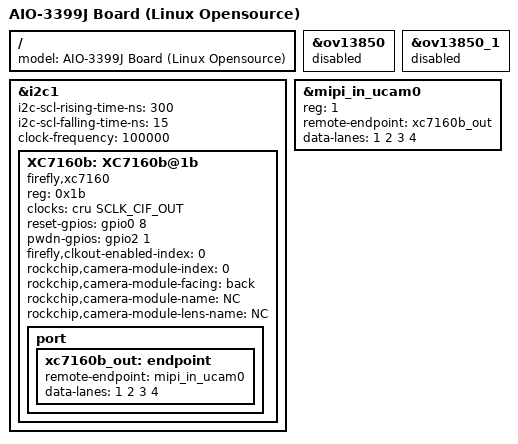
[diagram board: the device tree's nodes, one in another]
/*
 * Copyright (c) 2016 Fuzhou Rockchip Electronics Co., Ltd
 *
 * This file is dual-licensed: you can use it either under the terms
 * of the GPL or the X11 license, at your option. Note that this dual
 * licensing only applies to this file, and not this project as a
 * whole.
 *
 *  a) This file is free software; you can redistribute it and/or
 *     modify it under the terms of the GNU General Public License as
 *     published by the Free Software Foundation; either version 2 of the
 *     License, or (at your option) any later version.
 *
 *     This file is distributed in the hope that it will be useful,
 *     but WITHOUT ANY WARRANTY; without even the implied warranty of
 *     MERCHANTABILITY or FITNESS FOR A PARTICULAR PURPOSE.  See the
 *     GNU General Public License for more details.
 *
 * Or, alternatively,
 *     restriction, including without limitation the rights to use,
 *     copy, modify, merge, publish, distribute, sublicense, and/or
 *     sell copies of the Software, and to permit persons to whom the
 *     Software is furnished to do so, subject to the following
 *     conditions:
 *
 *     The above copyright notice and this permission notice shall be
 *     included in all copies or substantial portions of the Software.
 *
 *     THE SOFTWARE IS PROVIDED "AS IS", WITHOUT WARRANTY OF ANY KIND,
 *     EXPRESS OR IMPLIED, INCLUDING BUT NOT LIMITED TO THE WARRANTIES
 *     OF MERCHANTABILITY, FITNESS FOR A PARTICULAR PURPOSE AND
 *     NONINFRINGEMENT. IN NO EVENT SHALL THE AUTHORS OR COPYRIGHT
 *     HOLDERS BE LIABLE FOR ANY CLAIM, DAMAGES OR OTHER LIABILITY,
 *     WHETHER IN AN ACTION OF CONTRACT, TORT OR OTHERWISE, ARISING
 *     FROM, OUT OF OR IN CONNECTION WITH THE SOFTWARE OR THE USE OR
 *     OTHER DEALINGS IN THE SOFTWARE.
 */

/dts-v1/;

#include "rk3399-firefly-aio.dtsi"

/ {
	model = "AIO-3399J Board (Linux Opensource)";
};


&ov13850 {
	status = "disabled";
};

&ov13850_1 {
	status = "disabled";
};


&i2c1 {
	status = "okay";
	i2c-scl-rising-time-ns = <300>;
	i2c-scl-falling-time-ns = <15>;
	clock-frequency = <100000>;

	XC7160b: XC7160b@1b{
        status = "okay";
        compatible = "firefly,xc7160";
        reg = <0x1b>;
        clocks = <&cru SCLK_CIF_OUT>;
        clock-names = "xvclk";

        reset-gpios = <&gpio0 8 GPIO_ACTIVE_HIGH>;	/*GPIO0_B0 MIP_RST*/
		pwdn-gpios = <&gpio2 1 GPIO_ACTIVE_HIGH>;	/*GPIO2_A1  DVP_PDN1_H*/
		pinctrl-names = "rockchip,camera_default", "rockchip,camera_sleep";

        firefly,clkout-enabled-index = <0>;
        rockchip,camera-module-index = <0>;
        rockchip,camera-module-facing = "back";
        rockchip,camera-module-name = "NC";
        rockchip,camera-module-lens-name = "NC";
        port {
			xc7160b_out: endpoint {
				remote-endpoint = <&mipi_in_ucam0>;
                data-lanes = <1 2 3 4>;
            };
        };
    };
};


&mipi_in_ucam0 {
    reg = <1>;
    remote-endpoint = <&xc7160b_out>;
    data-lanes = <1 2 3 4>;
};
